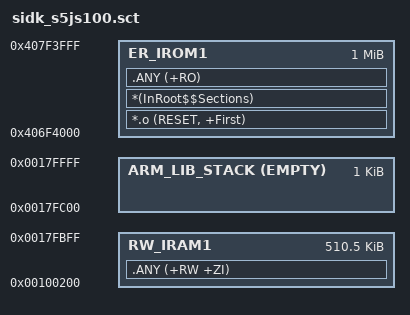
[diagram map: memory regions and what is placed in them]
#! armcc -E
;/****************************************************************************
; *
; * Copyright 2020 Samsung Electronics All Rights Reserved.
; * SPDX-License-Identifier: Apache-2.0
; *
; * Licensed under the Apache License, Version 2.0 (the "License");
; * you may not use this file except in compliance with the License.
; * You may obtain a copy of the License at
; *
; * http://www.apache.org/licenses/LICENSE-2.0
; *
; * Unless required by applicable law or agreed to in writing,
; * software distributed under the License is distributed on an
; * "AS IS" BASIS, WITHOUT WARRANTIES OR CONDITIONS OF ANY KIND,
; * either express or implied. See the License for the specific
; * language governing permissions and limitations under the License.
; *
; ****************************************************************************/

#define S5JS100_BOOTMEM_BASE    (0x00000000)
#define S5JS100_BOOTMEM_END     (S5JS100_BOOTMEM_BASE + 0x2000)
#define S5JS100_IRAM_BASE       (0x00100000)
#define S5JS100_IRAM_SIZE       (0x00080000)
#define S5JS100_IRAM_END        (S5JS100_IRAM_BASE + S5JS100_IRAM_SIZE)
#define S5JS100_CODE_BASE       (0x406F4000)
#define S5JS100_CODE_SIZE       (0x00100000)
#define S5JS100_CODE_END        (S5JS100_CODE_BASE + S5JS100_CODE_SIZE)
#define S5JS100_FLASH_BASE      (0x40000000)
#define S5JS100_VECTOR_SIZE     (0x00000200)

#ifndef MBED_BOOT_STACK_SIZE
#define MBED_BOOT_STACK_SIZE 0x400
#endif

#define Stack_Size MBED_BOOT_STACK_SIZE

LR_IROM1 S5JS100_CODE_BASE S5JS100_CODE_SIZE  {    ; XIP region size_region

  ER_IROM1 S5JS100_CODE_BASE S5JS100_CODE_SIZE  {  ; XIP address = execution address
   *.o (RESET, +First)
   *(InRoot$$Sections)
   .ANY (+RO)
  }
  ;leave VECTOR address empty
  ;
  RW_IRAM1 (S5JS100_IRAM_BASE+S5JS100_VECTOR_SIZE) (S5JS100_IRAM_SIZE-S5JS100_VECTOR_SIZE-Stack_Size) {  ; RW data
   .ANY (+RW +ZI)
  }

  ARM_LIB_STACK (S5JS100_IRAM_END) EMPTY -Stack_Size { ; stack
  }
}

